# STM32C542 register map
File version: 1.0.0
CPU: CM33 r0p4, little endian, MPU, FPU, 4 interrupt priority bits
Registers are 32-bit, read-write, reset 0x0 unless marked. A register's access mark holds for its fields unless they carry their own. Offsets are from the block's base; [hi:lo] are bit positions; {n}, {i} and the like mark numbered series.

## CRS — CRS address block description
Base 0x40006000
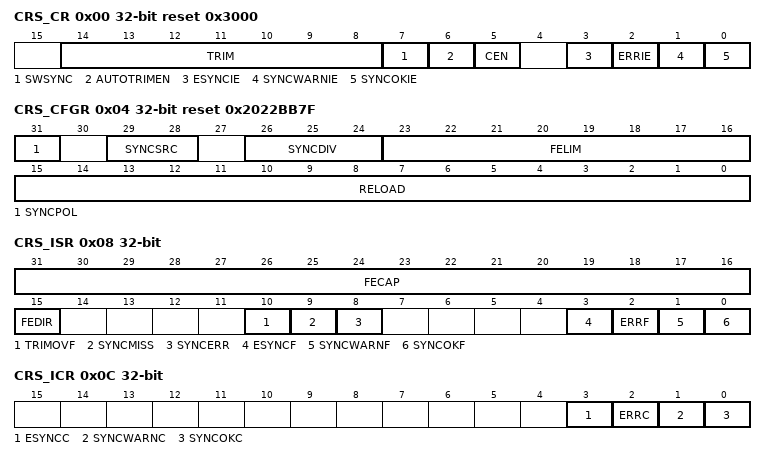
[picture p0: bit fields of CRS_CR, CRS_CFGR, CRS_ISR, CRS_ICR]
0x00 CRS_CR reset 0x3000 — CRS control register
  [14:8] TRIM — HSI144 oscillator smooth trimming
  [7] SWSYNC — Generate software SYNC event
    0=No action; 1=A software SYNC event is generated
  [6] AUTOTRIMEN — Automatic trimming enable
    0=Automatic trimming disabled, TRIM bits can be adjusted by the user; 1=Automatic trimming enabled, TRIM bits are read-only and under hardware control
  [5] CEN — Frequency error counter enable
    0=Frequency error counter disabled; 1=Frequency error counter enabled
  [3] ESYNCIE — Expected SYNC interrupt enable
    0=Expected SYNC (ESYNCF) interrupt disabled; 1=Expected SYNC (ESYNCF) interrupt enabled
  [2] ERRIE — Synchronization or trimming error interrupt enable
    0=Synchronization or trimming error (ERRF) interrupt disabled; 1=Synchronization or trimming error (ERRF) interrupt enabled
  [1] SYNCWARNIE — SYNC warning interrupt enable
    0=SYNC warning (SYNCWARNF) interrupt disabled; 1=SYNC warning (SYNCWARNF) interrupt enabled
  [0] SYNCOKIE — SYNC event OK interrupt enable
    0=SYNC event OK (SYNCOKF) interrupt disabled; 1=SYNC event OK (SYNCOKF) interrupt enabled
0x04 CRS_CFGR reset 0x2022BB7F — CRS configuration register
  [31] SYNCPOL — SYNC polarity selection
    0=SYNC active on rising edge (default); 1=SYNC active on falling edge
  [29:28] SYNCSRC — SYNC signal source selection
    {v}=crs_sync_in_{v} selected as SYNC signal source (v=0..3)
  [26:24] SYNCDIV — SYNC divider
    0=SYNC not divided (default); 1=SYNC divided by 2; 2=SYNC divided by 4; 3=SYNC divided by 8; 4=SYNC divided by 16; 5=SYNC divided by 32; 6=SYNC divided by 64; 7=SYNC divided by 128
  [23:16] FELIM — Frequency error limit
  [15:0] RELOAD — Counter reload value
0x08 CRS_ISR ro — CRS interrupt and status register
  [31:16] FECAP — Frequency error capture
  [15] FEDIR — Frequency error direction
    0=Up-counting direction, the actual frequency is above the target; 1=Down-counting direction, the actual frequency is below the target
  [10] TRIMOVF — Trimming overflow or underflow
    0=No trimming error signaled; 1=Trimming error signaled
  [9] SYNCMISS — SYNC missed
    0=No SYNC missed error signaled; 1=SYNC missed error signaled
  [8] SYNCERR — SYNC error
    0=No SYNC error signaled; 1=SYNC error signaled
  [3] ESYNCF — Expected SYNC flag
    0=No expected SYNC signaled; 1=Expected SYNC signaled
  [2] ERRF — Error flag
    0=No synchronization or trimming error signaled; 1=Synchronization or trimming error signaled
  [1] SYNCWARNF — SYNC warning flag
    0=No SYNC warning signaled; 1=SYNC warning signaled
  [0] SYNCOKF — SYNC event OK flag
    0=No SYNC event OK signaled; 1=SYNC event OK signaled
0x0C CRS_ICR — CRS interrupt flag clear register
  [3] ESYNCC — Expected SYNC clear flag
  [2] ERRC — Error clear flag
  [1] SYNCWARNC — SYNC warning clear flag
  [0] SYNCOKC — SYNC event OK clear flag

## HASH — HASH register bank
Base 0x420C0400
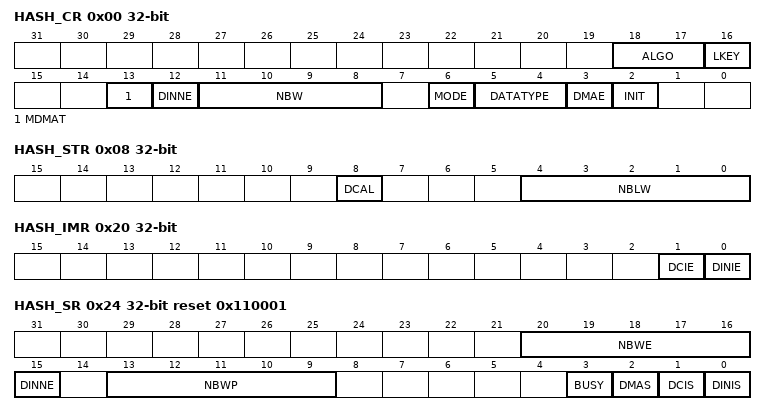
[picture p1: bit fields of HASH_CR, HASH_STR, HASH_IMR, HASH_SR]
0x00 HASH_CR — HASH control register
  [18:17] ALGO — Algorithm selection
    0=SHA-1; 2=SHA-224; 3=SHA-256
  [16] LKEY — Long key selection
    0=HMAC key is shorter or equal to the block size (short key); 1=HMAC key is longer than the block size (long key)
  [13] MDMAT — Multiple DMA transfers
    0=DCAL is automatically set at the end of a DMA transfer; 1=DCAL is not automatically set at the end of a DMA transfer
  [12] DINNE ro — DIN not empty
  [11:8] NBW ro — Number of words already pushed
  [6] MODE — Mode selection
    0=Hash mode selected; 1=HMAC mode selected
  [5:4] DATATYPE — Data type selection
    0=32-bit data; 1=16-bit data or half-word; 2=8-bit data or bytes; 3=bit data or bit string
  [3] DMAE — DMA enable
    0=DMA transfers disabled; 1=DMA transfers enabled
  [2] INIT — Initialize message digest calculation
0x04 HASH_DIN wo — HASH data input register
  [31:0] DATAIN — Data input
0x08 HASH_STR — HASH start register
  [8] DCAL — Digest calculation
  [4:0] NBLW — Number of valid bits in the last word
    0=All the 32 bits of the last data written are valid message bits, that is M[31:0]; 1=Only one bit of the last data written (after swapping) is valid, that is M[0]; 2=Only two bits of the last data written (after swapping) are valid, that is M[1:0]; 3=Only three bits of the last data written (after swapping) are valid that is M[2:0]; 31=Only 31 bits of the last data written (after swapping) are valid that is M[30:0]
{0xC+4i} HASH_HRA{i} ro (i=0..4) — HASH aliased digest register {i}
  [31:0] H{i} — Hash data x
0x20 HASH_IMR — HASH interrupt enable register
  [1] DCIE — Digest calculation completion interrupt enable
    0=Digest calculation completion interrupt disabled; 1=Digest calculation completion interrupt enabled
  [0] DINIE — Data input interrupt enable
    0=Data input interrupt disabled; 1=Data input interrupt enabled
0x24 HASH_SR reset 0x110001 — HASH status register
  [20:16] NBWE ro — Number of words expected
  [15] DINNE ro — DIN not empty
    0=No data are present in the data input buffer; 1=The input buffer contains at least one word of data
  [13:9] NBWP ro — Number of words already pushed
  [3] BUSY ro — Busy bit
    0=No block is currently being processed; 1=The hash core is processing a block of data
  [2] DMAS ro — DMA Status
    0=DMA interface is disabled (DMAE=0) and no transfer is ongoing; 1=DMA interface is enabled (DMAE=1) or a transfer is ongoing
  [1] DCIS — Digest calculation completion interrupt status
    0=No digest available in the HASH_HRx registers (zeros are returned); 1=Digest calculation complete, a digest is available in the HASH_HRx registers
  [0] DINIS — Data input interrupt status
    0=Less than 16 locations are free in the input buffer; 1=A new block can be entered into the input buffer
{0xF8+4i} HASH_CSR{i} (i=0..53) — HASH context swap register {i}
  [31:0] CS{i} — Context swap x
{0x310+4i} HASH_HR{i} ro (i=0..4) — HASH digest register {i}
  [31:0] H{i} — Hash data x
{0x310+4i} HASH_HR{i} ro (i=5..7) — HASH supplementary digest register {i}
  [31:0] H{i} — Hash data x
